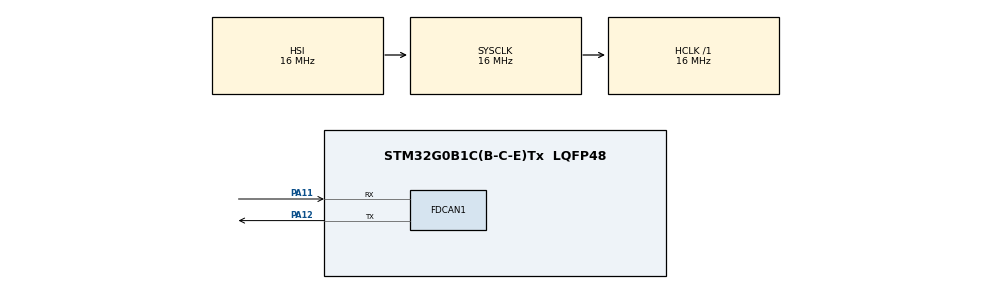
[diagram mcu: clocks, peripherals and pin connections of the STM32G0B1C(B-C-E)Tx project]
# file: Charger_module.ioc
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FDCAN1.AutoRetransmission=DISABLE
FDCAN1.CalculateBaudRateNominal=250000
FDCAN1.CalculateTimeBitNominal=4000
FDCAN1.CalculateTimeQuantumNominal=250.0
FDCAN1.ExtFiltersNbr=1
FDCAN1.Mode=FDCAN_MODE_NORMAL
FDCAN1.NominalPrescaler=4
FDCAN1.NominalTimeSeg1=13
FDCAN1.StdFiltersNbr=1
Mcu.Family=STM32G0
Mcu.Name=STM32G0B1C(B-C-E)Tx
Mcu.Package=LQFP48
NVIC.TIM16_FDCAN_IT0_IRQn=true\:0\:0\:false\:false\:true\:true\:true\:true
PA11\ [PA9].Mode=FDCAN_Activate
PA11\ [PA9].Signal=FDCAN1_RX
PA12\ [PA10].Mode=FDCAN_Activate
PA12\ [PA10].Signal=FDCAN1_TX
ProjectManager.HeapSize=0x200
ProjectManager.StackSize=0x400
ProjectManager.TargetToolchain=STM32CubeIDE
RCC.AHBFreq_Value=16000000
RCC.CortexFreq_Value=16000000
RCC.EXTERNAL_CLOCK_VALUE=48000
RCC.HCLKFreq_Value=16000000
RCC.HSE_VALUE=8000000
RCC.HSI48_VALUE=48000000
RCC.HSI_VALUE=16000000
RCC.LSE_VALUE=32768
RCC.SYSCLKFreq_VALUE=16000000
RCC.USBFreq_Value=48000000
RCC.VCOOutputFreq_Value=128000000
board=custom

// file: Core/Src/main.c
/* USER CODE BEGIN Header */
/**
  ******************************************************************************
  * @file           : main.c
  * @brief          : Main program body
  ******************************************************************************
  * @attention
  *
  * Copyright (c) 2025 STMicroelectronics.
  * All rights reserved.
  *
  * This software is licensed under terms that can be found in the LICENSE file
  * in the root directory of this software component.
  * If no LICENSE file comes with this software, it is provided AS-IS.
  *
  ******************************************************************************
  */
/* USER CODE END Header */
#include "main.h"

/* USER CODE BEGIN Includes */
#include "can.h"
#include "charger_module.h"
/* USER CODE END Includes */

FDCAN_HandleTypeDef hfdcan1;

/* USER CODE BEGIN PV */
FDCAN_TxHeaderTypeDef Tx_header;
FDCAN_RxHeaderTypeDef Rx_header;

bms_state state;
charger_to_bms rx_msg;
uint16_t set_curr;
uint16_t set_vol;
uint16_t rec_curr;
uint16_t rec_vol;
uint8_t chg_state;
/* USER CODE END PV */

void SystemClock_Config(void);
static void MX_GPIO_Init(void);
static void MX_FDCAN1_Init(void);
/* USER CODE BEGIN PFP */
void Check_Bms_State(bms_state state);
/* USER CODE END PFP */

int main(void)
{

  /* MCU Configuration--------------------------------------------------------*/

  /* Reset of all peripherals, Initializes the Flash interface and the Systick. */
  HAL_Init();

  /* Configure the system clock */
  SystemClock_Config();

  /* Initialize all configured peripherals */
  MX_GPIO_Init();
  MX_FDCAN1_Init();
  /* USER CODE BEGIN 2 */
  CAN_init();
  Charger_CAN_config();
  /* USER CODE END 2 */

  /* Infinite loop */
  /* USER CODE BEGIN WHILE */
  while (1)
  {

	  Check_Bms_State(state);
    /* USER CODE END WHILE */

  }
}

void SystemClock_Config(void)
{
  RCC_OscInitTypeDef RCC_OscInitStruct = {0};
  RCC_ClkInitTypeDef RCC_ClkInitStruct = {0};

  /** Configure the main internal regulator output voltage
  */
  HAL_PWREx_ControlVoltageScaling(PWR_REGULATOR_VOLTAGE_SCALE1);

  /** Initializes the RCC Oscillators according to the specified parameters
  * in the RCC_OscInitTypeDef structure.
  */
  RCC_OscInitStruct.OscillatorType = RCC_OSCILLATORTYPE_HSI;
  RCC_OscInitStruct.HSIState = RCC_HSI_ON;
  RCC_OscInitStruct.HSIDiv = RCC_HSI_DIV1;
  RCC_OscInitStruct.HSICalibrationValue = RCC_HSICALIBRATION_DEFAULT;
  RCC_OscInitStruct.PLL.PLLState = RCC_PLL_NONE;
  if (HAL_RCC_OscConfig(&RCC_OscInitStruct) != HAL_OK)
  {
    Error_Handler();
  }

  /** Initializes the CPU, AHB and APB buses clocks
  */
  RCC_ClkInitStruct.ClockType = RCC_CLOCKTYPE_HCLK|RCC_CLOCKTYPE_SYSCLK
                              |RCC_CLOCKTYPE_PCLK1;
  RCC_ClkInitStruct.SYSCLKSource = RCC_SYSCLKSOURCE_HSI;
  RCC_ClkInitStruct.AHBCLKDivider = RCC_SYSCLK_DIV1;
  RCC_ClkInitStruct.APB1CLKDivider = RCC_HCLK_DIV1;

  if (HAL_RCC_ClockConfig(&RCC_ClkInitStruct, FLASH_LATENCY_0) != HAL_OK)
  {
    Error_Handler();
  }
}

static void MX_FDCAN1_Init(void)
{

  hfdcan1.Instance = FDCAN1;
  hfdcan1.Init.ClockDivider = FDCAN_CLOCK_DIV1;
  hfdcan1.Init.FrameFormat = FDCAN_FRAME_CLASSIC;
  hfdcan1.Init.Mode = FDCAN_MODE_NORMAL;
  hfdcan1.Init.AutoRetransmission = DISABLE;
  hfdcan1.Init.TransmitPause = DISABLE;
  hfdcan1.Init.ProtocolException = DISABLE;
  hfdcan1.Init.NominalPrescaler = 4;
  hfdcan1.Init.NominalSyncJumpWidth = 1;
  hfdcan1.Init.NominalTimeSeg1 = 13;
  hfdcan1.Init.NominalTimeSeg2 = 2;
  hfdcan1.Init.DataPrescaler = 1;
  hfdcan1.Init.DataSyncJumpWidth = 1;
  hfdcan1.Init.DataTimeSeg1 = 1;
  hfdcan1.Init.DataTimeSeg2 = 1;
  hfdcan1.Init.StdFiltersNbr = 1;
  hfdcan1.Init.ExtFiltersNbr = 1;
  hfdcan1.Init.TxFifoQueueMode = FDCAN_TX_FIFO_OPERATION;
  if (HAL_FDCAN_Init(&hfdcan1) != HAL_OK)
  {
    Error_Handler();
  }

}

static void MX_GPIO_Init(void)
{

  /* GPIO Ports Clock Enable */
  __HAL_RCC_GPIOA_CLK_ENABLE();

}

/* USER CODE BEGIN 4 */

/*Function to check the BMS state*/
void Check_Bms_State(bms_state stat)
{
	switch(stat)
	{
		case SYNC_STATE:
		{
			set_curr = 0;
			set_vol = 58;
			chg_state = 0;
			Bms_Demand(chg_state, set_curr, set_vol);
			rx_msg = Charger_response();
			if(rx_msg.bat_chg_status == 0x02 || rx_msg.bat_chg_status == 0x12)
			{
				state = DEM_58V_50A;
			}
			break;
		}

		case DEM_58V_50A:
		{
			set_curr = 45;
			set_vol = 58;
			chg_state = 1;
			Bms_Demand(chg_state, set_curr, set_vol);
			rx_msg = Charger_response();
			rec_curr = Read_Current(rx_msg);
			rec_vol = Read_Voltage(rx_msg);
			if(rec_curr == set_curr /*&& rec_vol == set_vol*/)
			{
				HAL_Delay(10000);
				state = DEM_58V_40A;
			}
			break;
		}

		case DEM_58V_40A:
		{
			set_curr = 30;
			set_vol = 58;
			chg_state = 1;
			Bms_Demand(chg_state, set_curr, set_vol);
			rx_msg = Charger_response();
			rec_curr = Read_Current(rx_msg);
			rec_vol = Read_Voltage(rx_msg);
			if(rec_curr == set_curr /*&& rec_vol == set_vol*/)
			{
				HAL_Delay(10000);
				state = DEM_58V_30A;
			}
			break;
		}

		case DEM_58V_30A:
		{
			set_curr = 20;
			set_vol = 58;
			chg_state = 1;
			Bms_Demand(chg_state, set_curr, set_vol);
			rx_msg = Charger_response();
			rec_curr = Read_Current(rx_msg);
			rec_vol = Read_Voltage(rx_msg);
			if(rec_curr == set_curr /*&& rec_vol == set_vol*/)
			{
				HAL_Delay(10000);
				state = 100;
			}
			break;
		}

		default:
		{
			/*Turn Off Charger*/
			set_curr = 0;
			set_vol = 0;
			chg_state = 0;
			Bms_Demand(chg_state, set_curr, set_vol);
			HAL_Delay(30000);
			state = SYNC_STATE;
			break;
		}

	}
}

/* USER CODE END 4 */

void Error_Handler(void)
{
  __disable_irq();
  while (1)
  {
  }
}
